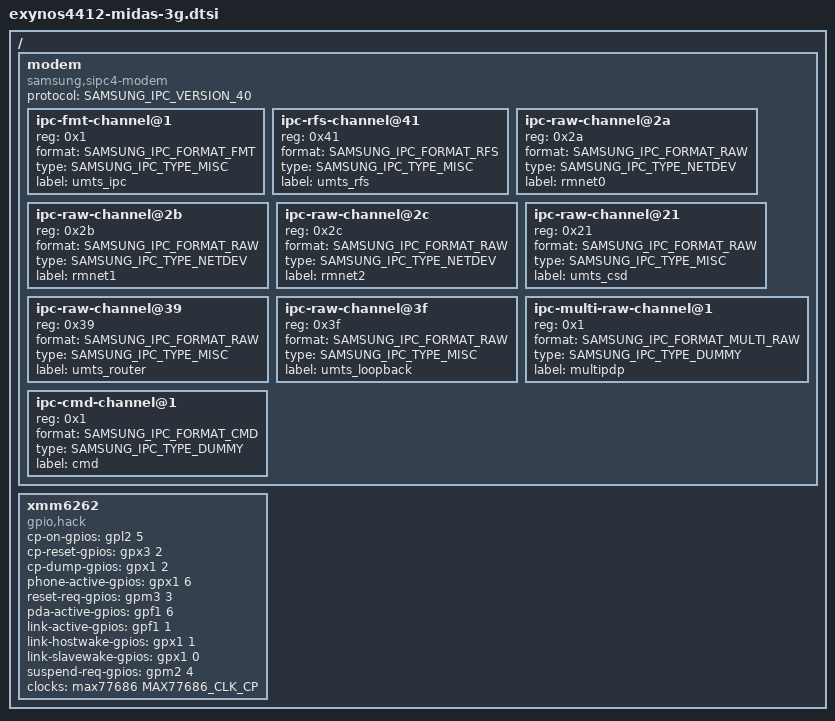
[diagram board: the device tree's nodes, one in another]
// SPDX-License-Identifier: GPL-2.0
//
// Copyright (C) 2018 Simon Shields <simon@lineageos.org>
//
// Configuration for the Infineon XMM6262 modem found in
// Exynos4412-based i9300, n7100, and trats2 boards.
//
//

#include <dt-bindings/gpio/gpio.h>
#include <dt-bindings/pinctrl/samsung.h>
#include <dt-bindings/net/samsung_ipc.h>
#include <dt-bindings/clock/maxim,max77686.h>

/ {
	modem {
		compatible = "samsung,sipc4-modem";
		protocol = <SAMSUNG_IPC_VERSION_40>;
		#size-cells = <0>;
		#address-cells = <1>;

		ipc-fmt-channel@1 {
			reg = <0x1>;
			format = <SAMSUNG_IPC_FORMAT_FMT>;
			type = <SAMSUNG_IPC_TYPE_MISC>;
			label = "umts_ipc";
		};

		ipc-rfs-channel@41 {
			reg = <0x41>;
			format = <SAMSUNG_IPC_FORMAT_RFS>;
			type = <SAMSUNG_IPC_TYPE_MISC>;
			label = "umts_rfs";
		};

		ipc-raw-channel@2a {
			reg = <0x2a>;
			format = <SAMSUNG_IPC_FORMAT_RAW>;
			type = <SAMSUNG_IPC_TYPE_NETDEV>;
			label = "rmnet0";
		};

		ipc-raw-channel@2b {
			reg = <0x2b>;
			format = <SAMSUNG_IPC_FORMAT_RAW>;
			type = <SAMSUNG_IPC_TYPE_NETDEV>;
			label = "rmnet1";
		};

		ipc-raw-channel@2c {
			reg = <0x2c>;
			format = <SAMSUNG_IPC_FORMAT_RAW>;
			type = <SAMSUNG_IPC_TYPE_NETDEV>;
			label = "rmnet2";
		};

		ipc-raw-channel@21 {
			reg = <0x21>;
			format = <SAMSUNG_IPC_FORMAT_RAW>;
			type = <SAMSUNG_IPC_TYPE_MISC>;
			label = "umts_csd";
		};

		ipc-raw-channel@39 {
			reg = <0x39>;
			format = <SAMSUNG_IPC_FORMAT_RAW>;
			type = <SAMSUNG_IPC_TYPE_MISC>;
			label = "umts_router";
		};

		ipc-raw-channel@3f {
			reg = <0x3f>;
			format = <SAMSUNG_IPC_FORMAT_RAW>;
			type = <SAMSUNG_IPC_TYPE_MISC>;
			label = "umts_loopback";
		};

		ipc-multi-raw-channel@1 {
			reg = <0x1>;
			format = <SAMSUNG_IPC_FORMAT_MULTI_RAW>;
			type = <SAMSUNG_IPC_TYPE_DUMMY>;
			label = "multipdp";
		};

		ipc-cmd-channel@1 {
			reg = <0x1>;
			format = <SAMSUNG_IPC_FORMAT_CMD>;
			type = <SAMSUNG_IPC_TYPE_DUMMY>;
			label = "cmd";
		};
	};

	xmm6262 {
        compatible = "gpio,hack";
        cp-on-gpios = <&gpl2 5 GPIO_ACTIVE_HIGH>;
        cp-reset-gpios = <&gpx3 2 GPIO_ACTIVE_HIGH>;
        cp-dump-gpios = <&gpx1 2 GPIO_ACTIVE_HIGH>;
        phone-active-gpios = <&gpx1 6 GPIO_ACTIVE_HIGH>;
        reset-req-gpios = <&gpm3 3 GPIO_ACTIVE_HIGH>;
        pda-active-gpios = <&gpf1 6 GPIO_ACTIVE_HIGH>;
        link-active-gpios = <&gpf1 1 GPIO_ACTIVE_HIGH>;
        link-hostwake-gpios = <&gpx1 1 GPIO_ACTIVE_HIGH>;
        link-slavewake-gpios = <&gpx1 0 GPIO_ACTIVE_HIGH>;
        suspend-req-gpios = <&gpm2 4 GPIO_ACTIVE_HIGH>;

		clocks = <&max77686 MAX77686_CLK_CP>;
		clock-names = "cp_clk";
    };

};
